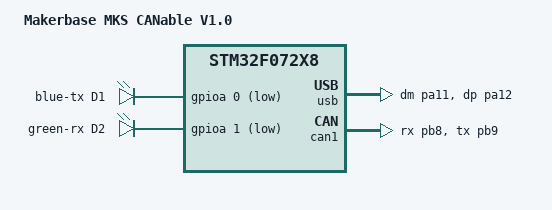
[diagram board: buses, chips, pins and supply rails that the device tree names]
/*
 * SPDX-FileCopyrightText: Copyright (c) 2026 Navimatix GmbH
 * SPDX-FileCopyrightText: Copyright (c) 2026 TiaC Systems
 * SPDX-License-Identifier: Apache-2.0
 */

/dts-v1/;

#include <st/f0/stm32f072X8.dtsi>
#include <st/f0/stm32f072c(8-b)tx-pinctrl.dtsi>

/ {
	model = "Makerbase MKS CANable V1.0";
	compatible = "makerbase,mks-canable-v10";

	chosen {
		zephyr,sram = &sram0;
		zephyr,flash = &flash0;
		zephyr,canbus = &can1;
	};

	aliases {
		led0 = &blue_led;
		led1 = &green_led;
	};

	leds: leds {
		compatible = "gpio-leds";

		blue_led: led_1 {
			gpios = <&gpioa 0 GPIO_ACTIVE_LOW>;
			label = "blue-tx D1";
		};

		green_led: led_2 {
			gpios = <&gpioa 1 GPIO_ACTIVE_LOW>;
			label = "green-rx D2";
		};
	};
};

&clk_hsi {
	/* Internal 8 MHz clock used to drive PLL */
	status = "okay";
	clock-frequency = <DT_FREQ_M(8)>;
};

/* Adjust the PLL for a SYSTEM Clock of 48 MHz  */
&pll {
	prediv = <1>;
	mul = <6>;
	clocks = <&clk_hsi>;
	status = "okay";
};

&rcc {
	clocks = <&pll>;
	clock-frequency = <DT_FREQ_M(48)>;
	ahb-prescaler = <1>;
	apb1-prescaler = <1>;
};

zephyr_udc0: &usb {
	pinctrl-0 = <&usb_dm_pa11 &usb_dp_pa12>;
	pinctrl-names = "default";
	status = "okay";
};

&can1 {
	pinctrl-0 = <&can_rx_pb8 &can_tx_pb9>;
	pinctrl-names = "default";
	status = "okay";

	can-transceiver {
		max-bitrate = <1000000>;
	};
};
